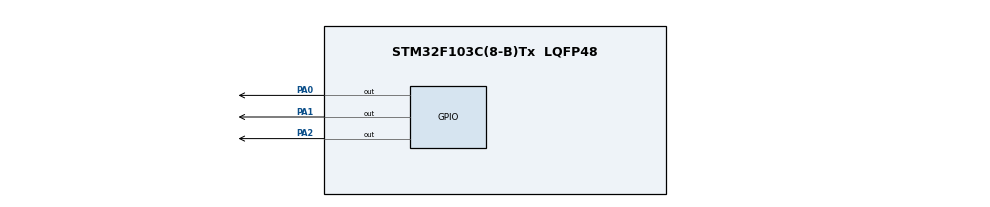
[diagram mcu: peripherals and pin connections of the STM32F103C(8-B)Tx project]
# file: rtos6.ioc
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FREERTOS.Tasks01=defaultTask,24,128,StartDefaultTask,Default,NULL,Dynamic,NULL,NULL;StartGreenLed,24,128,GreenLedTask,Default,NULL,Dynamic,NULL,NULL;StartRedLed,24,128,RedLedTask,Default,NULL,Dynamic,NULL,NULL
Mcu.Family=STM32F1
Mcu.Name=STM32F103C(8-B)Tx
Mcu.Package=LQFP48
NVIC.PriorityGroup=NVIC_PRIORITYGROUP_4
PA0-WKUP.Signal=GPIO_Output
PA1.Signal=GPIO_Output
PA13.Mode=Serial_Wire
PA13.Signal=SYS_JTMS-SWDIO
PA14.Mode=Serial_Wire
PA14.Signal=SYS_JTCK-SWCLK
PA2.Signal=GPIO_Output
ProjectManager.HeapSize=0x200
ProjectManager.StackSize=0x400
ProjectManager.TargetToolchain=STM32CubeIDE
RCC.APB1Freq_Value=8000000
RCC.APB2Freq_Value=8000000
VP_FREERTOS_VS_CMSIS_V2.Mode=CMSIS_V2
board=custom

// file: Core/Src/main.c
/* USER CODE BEGIN Header */
/**
  ******************************************************************************
  * @file           : main.c
  * @brief          : Main program body
  ******************************************************************************
  * @attention
  *
  * Copyright (c) 2024 STMicroelectronics.
  * All rights reserved.
  *
  * This software is licensed under terms that can be found in the LICENSE file
  * in the root directory of this software component.
  * If no LICENSE file comes with this software, it is provided AS-IS.
  *
  ******************************************************************************
  */
/* USER CODE END Header */
#include "main.h"
#include "cmsis_os.h"

/* USER CODE BEGIN Includes */
#include "task.h"
/* USER CODE END Includes */

/* Definitions for defaultTask */
osThreadId_t defaultTaskHandle;
const osThreadAttr_t defaultTask_attributes = {
  .name = "defaultTask",
  .stack_size = 128 * 4,
  .priority = (osPriority_t) osPriorityNormal,
};
/* Definitions for StartGreenLed */
osThreadId_t StartGreenLedHandle;
const osThreadAttr_t StartGreenLed_attributes = {
  .name = "StartGreenLed",
  .stack_size = 128 * 4,
  .priority = (osPriority_t) osPriorityNormal,
};
/* Definitions for StartRedLed */
osThreadId_t StartRedLedHandle;
const osThreadAttr_t StartRedLed_attributes = {
  .name = "StartRedLed",
  .stack_size = 128 * 4,
  .priority = (osPriority_t) osPriorityNormal,
};
/* USER CODE BEGIN PV */
uint8_t StartFlag; // 1 means Up, 0 means Down
volatile uint8_t RedFlag; // 1 means Up, 0 means Down
volatile uint8_t GreenFlag; // 1 means Up, 0 means Down
/* USER CODE END PV */

void SystemClock_Config(void);
static void MX_GPIO_Init(void);
void StartDefaultTask(void *argument);
void GreenLedTask(void *argument);
void RedLedTask(void *argument);

int main(void)
{

  /* USER CODE BEGIN 1 */
	StartFlag = 1;
	GreenFlag = 1;
	RedFlag = 1;
  /* USER CODE END 1 */

  /* MCU Configuration--------------------------------------------------------*/

  /* Reset of all peripherals, Initializes the Flash interface and the Systick. */
  HAL_Init();

  /* Configure the system clock */
  SystemClock_Config();

  /* Initialize all configured peripherals */
  MX_GPIO_Init();
  HAL_GPIO_WritePin(GPIOA, GPIO_PIN_2, GPIO_PIN_SET);

  /* Init scheduler */
  osKernelInitialize();

  /* Create the thread(s) */
  /* creation of defaultTask */
  defaultTaskHandle = osThreadNew(StartDefaultTask, NULL, &defaultTask_attributes);

  /* creation of StartGreenLed */
  StartGreenLedHandle = osThreadNew(GreenLedTask, NULL, &StartGreenLed_attributes);

  /* creation of StartRedLed */
  StartRedLedHandle = osThreadNew(RedLedTask, NULL, &StartRedLed_attributes);

  /* Start scheduler */
  osKernelStart();

  /* We should never get here as control is now taken by the scheduler */

  /* Infinite loop */
  while (1)
  {

  }
}

void SystemClock_Config(void)
{
  RCC_OscInitTypeDef RCC_OscInitStruct = {0};
  RCC_ClkInitTypeDef RCC_ClkInitStruct = {0};

  /** Initializes the RCC Oscillators according to the specified parameters
  * in the RCC_OscInitTypeDef structure.
  */
  RCC_OscInitStruct.OscillatorType = RCC_OSCILLATORTYPE_HSI;
  RCC_OscInitStruct.HSIState = RCC_HSI_ON;
  RCC_OscInitStruct.HSICalibrationValue = RCC_HSICALIBRATION_DEFAULT;
  RCC_OscInitStruct.PLL.PLLState = RCC_PLL_NONE;
  if (HAL_RCC_OscConfig(&RCC_OscInitStruct) != HAL_OK)
  {
    Error_Handler();
  }

  /** Initializes the CPU, AHB and APB buses clocks
  */
  RCC_ClkInitStruct.ClockType = RCC_CLOCKTYPE_HCLK|RCC_CLOCKTYPE_SYSCLK
                              |RCC_CLOCKTYPE_PCLK1|RCC_CLOCKTYPE_PCLK2;
  RCC_ClkInitStruct.SYSCLKSource = RCC_SYSCLKSOURCE_HSI;
  RCC_ClkInitStruct.AHBCLKDivider = RCC_SYSCLK_DIV1;
  RCC_ClkInitStruct.APB1CLKDivider = RCC_HCLK_DIV1;
  RCC_ClkInitStruct.APB2CLKDivider = RCC_HCLK_DIV1;

  if (HAL_RCC_ClockConfig(&RCC_ClkInitStruct, FLASH_LATENCY_0) != HAL_OK)
  {
    Error_Handler();
  }
}

static void MX_GPIO_Init(void)
{
  GPIO_InitTypeDef GPIO_InitStruct = {0};

  /* GPIO Ports Clock Enable */
  __HAL_RCC_GPIOA_CLK_ENABLE();

  /*Configure GPIO pin Output Level */
  HAL_GPIO_WritePin(GPIOA, GPIO_PIN_0|GPIO_PIN_1|GPIO_PIN_2, GPIO_PIN_RESET);

  /*Configure GPIO pins : PA0 PA1 PA2 */
  GPIO_InitStruct.Pin = GPIO_PIN_0|GPIO_PIN_1|GPIO_PIN_2;
  GPIO_InitStruct.Mode = GPIO_MODE_OUTPUT_PP;
  GPIO_InitStruct.Pull = GPIO_NOPULL;
  GPIO_InitStruct.Speed = GPIO_SPEED_FREQ_LOW;
  HAL_GPIO_Init(GPIOA, &GPIO_InitStruct);

}

/* USER CODE BEGIN 4 */
void AccessSharedData(void) {
    if (StartFlag == 1) {
        // Set Start flag to Down to indicate resource is in use
        StartFlag = 0;
    } else {
        // Resource contention: Turn on Blue LED
        HAL_GPIO_WritePin(GPIOA, GPIO_PIN_2, GPIO_PIN_SET);
    }

    // Simulate read/write operations with a delay of 500 milliseconds
    SimulateReadWriteOperation();

    // Set Start flag back to Up to indicate resource is free
    StartFlag = 1;

    // Turn off Blue LED (if it was turned on during contention)
    HAL_GPIO_WritePin(GPIOA, GPIO_PIN_2, GPIO_PIN_RESET);
}

void SimulateReadWriteOperation(void) {
    volatile uint32_t delay_count = 0;
    const uint32_t delay_target = 1000000; // Adjust this value to approximate 500 ms

    // Dummy loop to simulate processing time
    for (delay_count = 0; delay_count < delay_target; delay_count++) {
        __asm("nop"); // No Operation: Keeps the processor busy without changing code behavior
    }
}

/* USER CODE END 4 */

void StartDefaultTask(void *argument)
{
  for(;;)
  {
    osDelay(1);
  }
}

void GreenLedTask(void *argument)
{
  /* USER CODE BEGIN GreenLedTask */
  /* Infinite loop */
  for(;;)
  {
	  /* Turn on Green LED */
	  HAL_GPIO_WritePin(GPIOA, GPIO_PIN_0, GPIO_PIN_SET);

	  /* Access shared data (critical section) */
	  taskENTER_CRITICAL();
	  AccessSharedData();
	  taskEXIT_CRITICAL();

	  /* Turn off Green LED */
	  HAL_GPIO_WritePin(GPIOA, GPIO_PIN_0, GPIO_PIN_RESET);

	  /* Delay */
	  osDelay(100);
  }
  /* USER CODE END GreenLedTask */
}

void RedLedTask(void *argument)
{
  /* USER CODE BEGIN RedLedTask */
  /* Infinite loop */
  for(;;)
  {
	  /* Turn on Red LED */
	  HAL_GPIO_WritePin(GPIOA, GPIO_PIN_1, GPIO_PIN_SET);

	  /* Access shared data (critical section) */
	  taskENTER_CRITICAL();
	  AccessSharedData();
	  taskEXIT_CRITICAL();

	  /* Turn off Red LED */
	  HAL_GPIO_WritePin(GPIOA, GPIO_PIN_1, GPIO_PIN_RESET);

	  /* Delay */
	  osDelay(500);
  }
  /* USER CODE END RedLedTask */
}

void Error_Handler(void)
{
  __disable_irq();
  while (1)
  {
  }
}
